# STM32L471 register map
File version: 1.0
CPU: CM4 r0p1, little endian, MPU, FPU, 4 interrupt priority bits
Registers are 32-bit, read-write, reset 0x0 unless marked. A register's access mark holds for its fields unless they carry their own. Offsets are from the block's base; [hi:lo] are bit positions; {n}, {i} and the like mark numbered series; 'fields as' and 'values as' point back to an identical list.

## LCD — Liquid crystal display controller
Base 0x40002400
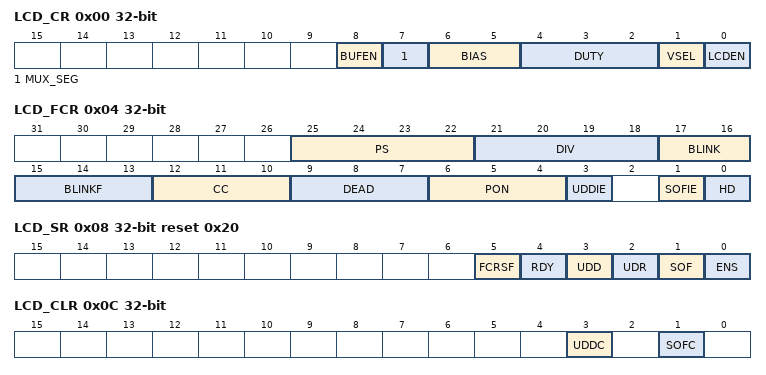
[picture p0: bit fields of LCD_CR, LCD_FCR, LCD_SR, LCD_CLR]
0x00 LCD_CR — LCD control register
  [8] BUFEN — Voltage output buffer enable This bit is used to enable/disable the voltage output buffer for higher driving capability.
    0=Output buffer disabled; 1=Output buffer enabled
  [7] MUX_SEG — Mux segment enable This bit is used to enable SEG pin remapping. Four SEG pins can be multiplexed with SEG[31:28] or SEG[15:12]. See Sectionm19.3.7.
    0=SEG pin multiplexing disabled; 1=SEG[31:28] are multiplexed with SEG[43:40]
  [6:5] BIAS — Bias selector These bits determine the bias used. Value 11 is forbidden.
    0=Bias 1/4; 1=Bias 1/2; 2=Bias 1/3
  [4:2] DUTY — Duty selection These bits determine the duty cycle.Unused COM pins can serve as general purpose input pins if COMIN is set. Values 101, 110 and 111 are forbidden. Others: Reserved
    0=Static duty; 1=1/2 duty; 2=1/3 duty; 3=1/4 duty; 4=1/8 duty
  [1] VSEL — Voltage source selection The VSEL bit determines the voltage source for the LCD.
    0=Internal source (voltage step-up converter); 1=External source (VLCD pin)
  [0] LCDEN — LCD controller enable This bit is set by software to enable the LCD Controller/Driver. It is cleared by software to turn off the LCD at the beginning of the next frame. When the LCD is disabled all COM and SEG pins are driven to V<sub>SS</sub>.
    0=LCD controller disabled; 1=LCD controller enabled
0x04 LCD_FCR — LCD frame control register
  [25:22] PS — PS 16-bit prescaler
    0=ck_ps = LCDCLK; 1=ck_ps = LCDCLK/2; 15=ck_ps = LCDCLK/32768
  [21:18] DIV — DIV clock divider
    0=ck_div = ck_ps/16; 1=ck_div = ck_ps/17; 15=ck_div = ck_ps/31
  [17:16] BLINK — Blink mode selection
    0=Blink disabled; 1=Blink enabled on SEG[0], COM[0] (1 pixel); 2=Blink enabled on SEG[0], all COMs (up to 8 pixels depending on the programmed duty); 3=Blink enabled on all SEGs and all COMs (all pixels)
  [15:13] BLINKF — Blink frequency selection
    0=f<sub>LCD</sub>/8; 1=f<sub>LCD</sub>/16; 2=f<sub>LCD</sub>/32; 3=f<sub>LCD</sub>/64; 4=f<sub>LCD</sub>/128; 5=f<sub>LCD</sub>/256; 6=f<sub>LCD</sub>/512; 7=f<sub>LCD</sub>/1024
  [12:10] CC — Contrast control
    {v}=V<sub>LCD{v}</sub> (v=0..7)
  [9:7] DEAD — Dead time duration These bits are written by software to configure the length of the dead time between frames. During the dead time the COM and SEG voltage levels are held at 0 V to reduce the contrast without modifying the frame rate. ......
    0=No dead time; 1=1 phase period dead time; 2=2 phase period dead time; 7=7 phase period dead time
  [6:4] PON — Pulse ON duration These bits are written by software to define the pulse duration in terms of ck_ps pulses. Amshort pulse leads to lower power consumption, but displays with high internal resistance may need a longer pulse to achieve satisfactory contrast. Note that the pulse is never longer than one half prescaled LCD clock period. PON duration example with LCDCLK = 32.768mkHz and PS=0x03:
    0=0 ms; 1=244 ms; 2=488 ms; 3=782 ms; 4=976 ms; 5=1.22 ms; 6=1.46 ms; 7=1.71 ms
  [3] UDDIE — Update display done interrupt enable This bit is set and cleared by software.
    0=LCD Update display done interrupt disabled; 1=LCD Update display done interrupt enabled
  [1] SOFIE — Start of frame interrupt enable This bit is set and cleared by software.
    0=LCD start-of-frame interrupt disabled; 1=LCD start-of-frame interrupt enabled
  [0] HD — High drive enable This bit is written by software to enable a low resistance divider. Displays with high internal resistance may need a longer drive time to achieve satisfactory contrast. This bit is useful in this case if some additional power consumption can be tolerated.
    0=Permanent high drive disabled; 1=Permanent high drive enabled. When HD=1, then the PON bits have to be programmed tom001.
0x08 LCD_SR access per field reset 0x20 — LCD status register
  [5] FCRSF ro — LCD frame control register synchronization flag This bit is set by hardware each time the LCD_FCR register is updated in the LCDCLK domain. It is cleared by hardware when writing to the LCD_FCR register.
    0=LCD frame control register not yet synchronized; 1=LCD frame control register synchronized
  [4] RDY ro — Ready flag This bit is set and cleared by hardware. It indicates the status of the step-up converter.
    0=Not ready; 1=Step-up converter is enabled and ready to provide the correct voltage
  [3] UDD ro — Update display done This bit is set by hardware. It is cleared by writing 1 to the UDDC bit in the LCD_CLR register. The bit set has priority over the clear. If the device is in Stop mode (PCLK not provided), UDD does not generate an interrupt even if UDDIE = 1. If the display is not enabled the UDD interrupt never occurs.
    0=No event; 1=Update Display Request done
  [2] UDR rw — Update display request
    0=No effect; 1=Update display request
  [1] SOF ro — Start-of-frame flag This bit is set by hardware at the beginning of a new frame, at the same time as the display data is updated. It is cleared by writing a 1 to the SOFC bit in the LCD_CLR register. The bit clear has priority over the set.
    0=No event; 1=Start-of-frame event occurred
  [0] ENS ro — LCD enabled status This bit is set and cleared by hardware. It indicates the LCD controller status. The ENS bit is set immediately when the LCDEN bit in the LCD_CR goes from 0 to 1. On deactivation it reflects the real status of LCD so it becomes 0 at the end of the last displayed frame.
    0=LCD controller disabled; 1=LCD controller enabled
0x0C LCD_CLR wo — LCD clear register
  [3] UDDC — Update display done clear This bit is written by software to clear the UDD flag in the LCD_SR register.
    0=No effect; 1=Clear UDD flag
  [1] SOFC — Start of frame flag clear This bit is written by software to clear the SOF flag in the LCD_SR register.
    0=No effect; 1=Clear SOF flag
0x14 LCD_RAM0 — LCD display memory
  [31:0] SEGMENT_DATA — Each bit corresponds to one pixel of the LCD display.
    0=Pixel inactive; 1=Pixel active
0x18 LCD_RAM1 — LCD display memory
  [11:0] SEGMENT_DATA — Each bit corresponds to one pixel of the LCD display.
    0=Pixel inactive; 1=Pixel active
0x1C LCD_RAM2 — LCD display memory
  fields as LCD_RAM0
0x20 LCD_RAM3 — LCD display memory
  fields as LCD_RAM1
0x24 LCD_RAM4 — LCD display memory
  fields as LCD_RAM0
0x28 LCD_RAM5 — LCD display memory
  fields as LCD_RAM1
0x2C LCD_RAM6 — LCD display memory
  fields as LCD_RAM0
0x30 LCD_RAM7 — LCD display memory
  fields as LCD_RAM1
0x34 LCD_RAM8 — LCD display memory
  fields as LCD_RAM0
0x38 LCD_RAM9 — LCD display memory
  [7:0] SEGMENT_DATA — Each bit corresponds to one pixel of the LCD display.
    0=Pixel inactive; 1=Pixel active
0x3C LCD_RAM10 — LCD display memory
  fields as LCD_RAM0
0x40 LCD_RAM11 — LCD display memory
  fields as LCD_RAM9
0x44 LCD_RAM12 — LCD display memory
  fields as LCD_RAM0
0x48 LCD_RAM13 — LCD display memory
  fields as LCD_RAM9
0x4C LCD_RAM14 — LCD display memory
  fields as LCD_RAM0
0x50 LCD_RAM15 — LCD display memory
  fields as LCD_RAM9

## Notices in the file
Copyright (c) 2024 STMicroelectronics.
SPDX-License-Identifier: Apache-2.0
Licensed under the Apache License, Version 2.0 (the "License");
you may not use this file except in compliance with the License.
You may obtain a copy of the License at
http://www.apache.org/licenses/LICENSE-2.0
Unless required by applicable law or agreed to in writing, software
distributed under the License is distributed on an "AS IS" BASIS,
WITHOUT WARRANTIES OR CONDITIONS OF ANY KIND, either express or implied.
See the License for the specific language governing permissions and
limitations under the License.
